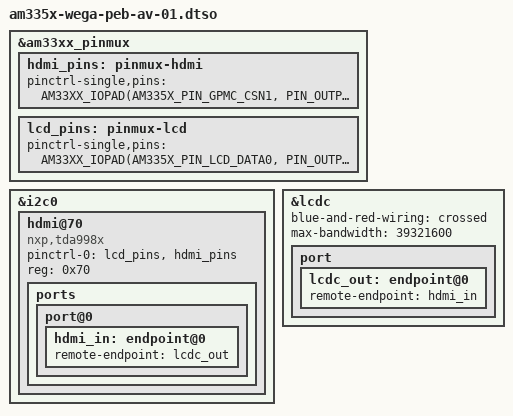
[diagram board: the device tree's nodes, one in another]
// SPDX-License-Identifier: (GPL-2.0+ OR MIT)
/*
 * Copyright (C) 2022 PHYTEC Messtechnik GmbH
 * Author: Dominik Haller <d.haller@phytec.de>
 */
/dts-v1/;
/plugin/;

#include <dt-bindings/pinctrl/am33xx.h>

&am33xx_pinmux {
	hdmi_pins: pinmux-hdmi {
		pinctrl-single,pins = <
			AM33XX_IOPAD(AM335X_PIN_GPMC_CSN1, PIN_OUTPUT | MUX_MODE7)	/* gpmc_csn1.x_av_int_gpio1_30	*/
		>;
	};

	lcd_pins: pinmux-lcd {
		pinctrl-single,pins = <
			AM33XX_IOPAD(AM335X_PIN_LCD_DATA0, PIN_OUTPUT | MUX_MODE0)
			AM33XX_IOPAD(AM335X_PIN_LCD_DATA1, PIN_OUTPUT | MUX_MODE0)
			AM33XX_IOPAD(AM335X_PIN_LCD_DATA2, PIN_OUTPUT | MUX_MODE0)
			AM33XX_IOPAD(AM335X_PIN_LCD_DATA3, PIN_OUTPUT | MUX_MODE0)
			AM33XX_IOPAD(AM335X_PIN_LCD_DATA4, PIN_OUTPUT | MUX_MODE0)
			AM33XX_IOPAD(AM335X_PIN_LCD_DATA5, PIN_OUTPUT | MUX_MODE0)
			AM33XX_IOPAD(AM335X_PIN_LCD_DATA6, PIN_OUTPUT | MUX_MODE0)
			AM33XX_IOPAD(AM335X_PIN_LCD_DATA7, PIN_OUTPUT | MUX_MODE0)
			AM33XX_IOPAD(AM335X_PIN_LCD_DATA8, PIN_OUTPUT | MUX_MODE0)
			AM33XX_IOPAD(AM335X_PIN_LCD_DATA9, PIN_OUTPUT | MUX_MODE0)
			AM33XX_IOPAD(AM335X_PIN_LCD_DATA10, PIN_OUTPUT | MUX_MODE0)
			AM33XX_IOPAD(AM335X_PIN_LCD_DATA11, PIN_OUTPUT | MUX_MODE0)
			AM33XX_IOPAD(AM335X_PIN_LCD_DATA12, PIN_OUTPUT | MUX_MODE0)
			AM33XX_IOPAD(AM335X_PIN_LCD_DATA13, PIN_OUTPUT | MUX_MODE0)
			AM33XX_IOPAD(AM335X_PIN_LCD_DATA14, PIN_OUTPUT | MUX_MODE0)
			AM33XX_IOPAD(AM335X_PIN_LCD_DATA15, PIN_OUTPUT | MUX_MODE0)
			AM33XX_IOPAD(AM335X_PIN_GPMC_AD15, PIN_OUTPUT | MUX_MODE1)	/* gpmc_ad15.lcd_data16 */
			AM33XX_IOPAD(AM335X_PIN_GPMC_AD14, PIN_OUTPUT | MUX_MODE1)	/* gpmc_ad14.lcd_data17 */
			AM33XX_IOPAD(AM335X_PIN_GPMC_AD13, PIN_OUTPUT | MUX_MODE1)	/* gpmc_ad13.lcd_data18 */
			AM33XX_IOPAD(AM335X_PIN_GPMC_AD12, PIN_OUTPUT | MUX_MODE1)	/* gpmc_ad12.lcd_data19 */
			AM33XX_IOPAD(AM335X_PIN_GPMC_AD11, PIN_OUTPUT | MUX_MODE1)	/* gpmc_ad11.lcd_data20 */
			AM33XX_IOPAD(AM335X_PIN_GPMC_AD10, PIN_OUTPUT | MUX_MODE1)	/* gpmc_ad10.lcd_data21 */
			AM33XX_IOPAD(AM335X_PIN_GPMC_AD9, PIN_OUTPUT | MUX_MODE1)	/* gpmc_ad9.lcd_data22 */
			AM33XX_IOPAD(AM335X_PIN_GPMC_AD8, PIN_OUTPUT | MUX_MODE1)	/* gpmc_ad8.lcd_data23 */
			AM33XX_IOPAD(AM335X_PIN_LCD_VSYNC, PIN_OUTPUT | MUX_MODE0)
			AM33XX_IOPAD(AM335X_PIN_LCD_HSYNC, PIN_OUTPUT | MUX_MODE0)
			AM33XX_IOPAD(AM335X_PIN_LCD_PCLK, PIN_OUTPUT | MUX_MODE0)
			AM33XX_IOPAD(AM335X_PIN_LCD_AC_BIAS_EN, PIN_OUTPUT | MUX_MODE0)
		>;
	};
};

&i2c0 {
	#address-cells = <1>;
	#size-cells = <0>;

	hdmi@70 {
		compatible = "nxp,tda998x";
		pinctrl-0 = <&lcd_pins &hdmi_pins>;
		pinctrl-names = "default";
		reg = <0x70>;

		ports {
			#address-cells = <1>;
			#size-cells = <0>;

			port@0 {
				hdmi_in: endpoint@0 {
					remote-endpoint = <&lcdc_out>;
				};
			};
		};
	};
};

&lcdc {
	blue-and-red-wiring = "crossed";
	max-bandwidth = <39321600>;
	status = "okay";

	port {
		lcdc_out: endpoint@0 {
			remote-endpoint = <&hdmi_in>;
		};
	};

};
